# STM32WL5X_CM0P register map
File version: 2.1
CPU: CM0 r0p1, little endian, MPU, no FPU, 4 interrupt priority bits
Registers are 32-bit, read-write, reset 0x0 unless marked. A register's access mark holds for its fields unless they carry their own. Offsets are from the block's base; [hi:lo] are bit positions.

## IWDG — Independent watchdog
Base 0x40003000
0x00 KR 16-bit wo — Key register
  [15:0] KEY — Key value (write only, read 0x0000)
    0x5555=Unlock (Enable access to PR, RLR and WINR registers); 0xAAAA=Feed watchdog with RLR register value; 0xCCCC=Start the watchdog
0x04 PR 16-bit reset 0x7 — Prescaler register
  [2:0] PR — Prescaler divider
    0=DivideBy4 (Divider /4); 1=DivideBy8 (Divider /8); 2=DivideBy16 (Divider /16); 3=DivideBy32 (Divider /32); 4=DivideBy64 (Divider /64); 5=DivideBy128 (Divider /128); other=DivideBy256 (Divider /256)
0x08 RLR 16-bit reset 0xFFF — Reload register
  [11:0] RL — Watchdog counter reload value
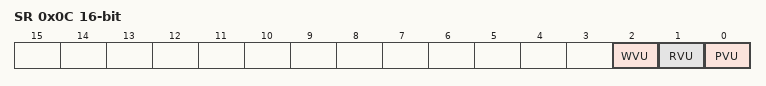
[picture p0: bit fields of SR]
0x0C SR 16-bit ro — Status register
  [all] fields
    0=Idle (No update on-going); 1=Busy (Update on-going)
  [2] WVU — Watchdog counter window value update
  [1] RVU — Watchdog counter reload value update
  [0] PVU — Watchdog prescaler value update

## PKA — Public key accelerator
Base 0x58002000
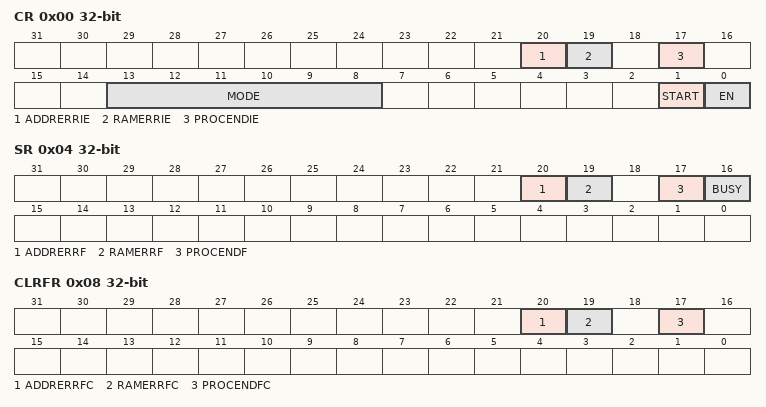
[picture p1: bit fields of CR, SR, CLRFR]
0x00 CR — control register
  [20] ADDRERRIE — Address error interrupt enable
    0=Disabled (No interrupt is generated when ADDRERRF flag is set in PKA_SR); 1=Enabled (An interrupt is generated when ADDRERRF flag is set in PKA_SR)
  [19] RAMERRIE — RAM error interrupt enable
    0=Disabled (No interrupt is generated when RAMERRF flag is set in PKA_SR); 1=Enabled (An interrupt is generated when RAMERRF flag is set in PKA_SR)
  [17] PROCENDIE
    0=Disabled (No interrupt is generated when PROCENDF flag is set in PKA_SR); 1=Enabled (An interrupt is generated when PROCENDF flag is set in PKA_SR)
  [13:8] MODE — PKA operation code
    0=MontgomeryCompExp (Montgomery parameter computation then modular exponentiation); 1=MontgomeryComp (Montgomery parameter computation only); 2=MontgomeryExp (Modular exponentiation only (Montgomery parameter must be loaded first)); 7=RSA (RSA CRT exponentiation); 8=Modular inversion; 9=Arithmetic addition; 10=Arithmetic subtraction; 11=Arithmetic multiplication; 12=Arithmetic comparison; 13=Modular reduction; 14=Modular addition; 15=Modular subtraction; 16=ModularMul (Montgomery multiplication); 32=MontgomeryCompScalar (Montgomery parameter computation then ECC scalar multiplication); 34=MontgomeryScalar (ECC scalar multiplication only (Montgomery parameter must be loaded first)); 36=ECDSASign; 38=ECDSA verification; 40=Elliptic (Point on elliptic curve Fp check)
  [1] START — start the operation
    on write: 1=Start (Writing 1 to this bit starts the operation which is selected by MODE[5:0], using the operands and data already written to the PKA RAM - This bit is always read as 0)
  [0] EN — PKA enable.
    0=Disabled (Disable PKA); 1=Enabled (Enable PKA)
0x04 SR ro — status register
  [20] ADDRERRF — Address error flag
    0=NoError; 1=Error (Address access is out of range (unmapped address))
  [19] RAMERRF — PKA RAM error flag
    0=NoError; 1=Error (An AHB access to the PKA RAM occurred while the PKA core was computing and using its internal RAM (AHB PKA_RAM access are not allowed while PKA operation is in progress))
  [17] PROCENDF — PKA End of Operation flag
    0=InProgress (Operation in progress); 1=Completed (PKA operation is completed - set when BUSY is deasserted)
  [16] BUSY — PKA operation is in progressThis bit is set to 1 whenever START bit in the PKA_CR is set. It is automatically cleared when the computation is complete, meaning that PKA RAM can be safely accessed and a new operation can be started.
    0=Idle (No operation in pgoress); 1=Busy (Operation in progress)
0x08 CLRFR wo — clear flag register
  [20] ADDRERRFC — Clear Address error flag
    1=Clear ADDRERRF flag
  [19] RAMERRFC — Clear PKA RAM error flag
    1=Clear RAMERRF flag
  [17] PROCENDFC — Clear PKA End of Operation flag
    1=Clear PROCENDF flag
